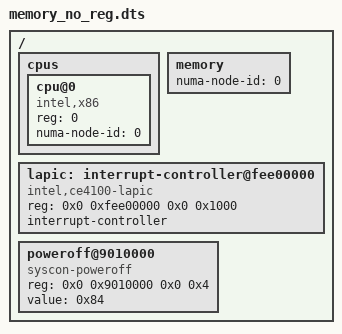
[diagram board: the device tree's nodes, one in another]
/dts-v1/;

/ {
	#address-cells = <2>;
	#size-cells = <2>;

	cpus {
		#address-cells = <1>;
		#size-cells = <0>;
		cpu@0 {
			device_type = "cpu";
			reg = <0>;
			compatible = "intel,x86";
			numa-node-id = <0>;
		};
	};

	/* No `reg` property -> MissingProperty { site: Memory, property: "reg" }
	 * (numa-node-id forces extract_numa to walk memory and fail). */
	memory {
		device_type = "memory";
		numa-node-id = <0>;
	};

		lapic: interrupt-controller@fee00000 {
		compatible = "intel,ce4100-lapic";
		reg = <0x0 0xfee00000 0x0 0x1000>;
		interrupt-controller;
		#interrupt-cells = <2>;
	};
		poweroff@9010000 {
		compatible = "syscon-poweroff";
		reg = <0x0 0x9010000 0x0 0x4>;
		value = <0x84>;
	};
};
